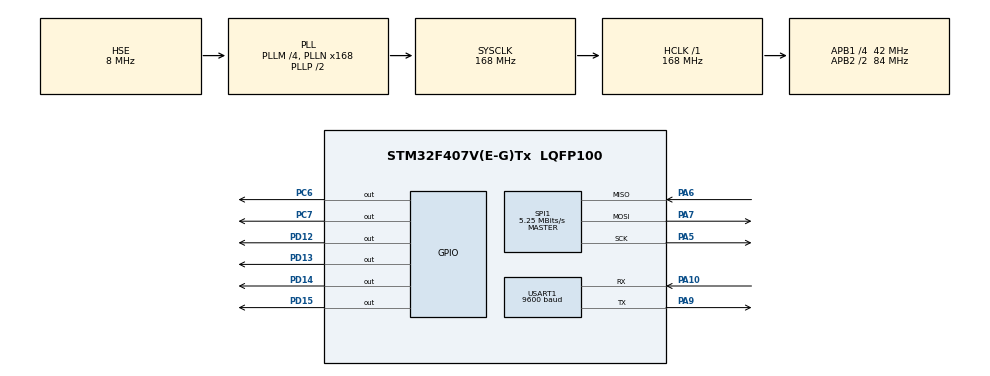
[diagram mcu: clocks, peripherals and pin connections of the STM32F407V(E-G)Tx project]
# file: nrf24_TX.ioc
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Mcu.Family=STM32F4
RCC.PLLSourceVirtual=RCC_PLLSOURCE_HSE
PA6.Mode=Full_Duplex_Master
PH0-OSC_IN.Signal=RCC_OSC_IN
RCC.CortexFreq_Value=168000000
PA7.Mode=Full_Duplex_Master
PA10.Mode=Asynchronous
SPI1.VirtualType=VM_MASTER
USART1.BaudRate=9600
PC6.Signal=GPIO_Output
RCC.APB1CLKDivider=RCC_HCLK_DIV4
RCC.SYSCLKSource=RCC_SYSCLKSOURCE_PLLCLK
ProjectManager.StackSize=0x400
PD13.Signal=GPIO_Output
PA9.Mode=Asynchronous
ProjectManager.TargetToolchain=STM32CubeIDE
SPI1.Direction=SPI_DIRECTION_2LINES
RCC.HCLKFreq_Value=168000000
RCC.APB2TimFreq_Value=168000000
PA9.Signal=USART1_TX
PC7.Signal=GPIO_Output
SPI1.CalculateBaudRate=5.25 MBits/s
RCC.LSE_VALUE=32768
RCC.AHBFreq_Value=168000000
PH0-OSC_IN.Mode=HSE-External-Oscillator
PA5.Signal=SPI1_SCK
RCC.HSE_VALUE=8000000
board=custom
RCC.VCOOutputFreq_Value=336000000
NVIC.SPI1_IRQn=true\:0\:0\:false\:false\:true\:true\:true
RCC.APB2Freq_Value=84000000
SPI1.Mode=SPI_MODE_MASTER
PH1-OSC_OUT.Signal=RCC_OSC_OUT
Mcu.Name=STM32F407V(E-G)Tx
PD14.Signal=GPIO_Output
PH1-OSC_OUT.Mode=HSE-External-Oscillator
RCC.48MHZClocksFreq_Value=84000000
RCC.SYSCLKFreq_VALUE=168000000
Mcu.Package=LQFP100
PA6.Signal=SPI1_MISO
PD12.Signal=GPIO_Output
USART1.VirtualMode=VM_ASYNC
PA10.Signal=USART1_RX
ProjectManager.HeapSize=0x200
RCC.HSI_VALUE=16000000
NVIC.PriorityGroup=NVIC_PRIORITYGROUP_4
RCC.APB2CLKDivider=RCC_HCLK_DIV2
RCC.PLLM=4
RCC.PLLN=168
RCC.APB1TimFreq_Value=84000000
NVIC.USART1_IRQn=true\:0\:0\:false\:false\:true\:true\:true
RCC.APB1Freq_Value=42000000
SPI1.BaudRatePrescaler=SPI_BAUDRATEPRESCALER_16
PD15.Signal=GPIO_Output
PA5.Mode=Full_Duplex_Master
PA7.Signal=SPI1_MOSI

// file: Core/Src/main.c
/* USER CODE BEGIN Header */
/**
  ******************************************************************************
  * @file           : main.c
  * @brief          : Main program body
  ******************************************************************************
  * @attention
  *
  * <h2><center>&copy; Copyright (c) 2021 STMicroelectronics.
  * All rights reserved.</center></h2>
  *
  * This software component is licensed by ST under BSD 3-Clause license,
  * the "License"; You may not use this file except in compliance with the
  * License. You may obtain a copy of the License at:
  *                        opensource.org/licenses/BSD-3-Clause
  *
  ******************************************************************************
  */
/* USER CODE END Header */
#include "main.h"

SPI_HandleTypeDef hspi1;

UART_HandleTypeDef huart1;

void SystemClock_Config(void);
static void MX_GPIO_Init(void);
static void MX_SPI1_Init(void);
static void MX_USART1_UART_Init(void);

/* USER CODE BEGIN 0 */
uint8_t RxData[32];
uint8_t flag=0;
uint8_t data[50];
uint8_t Tx=0,Rx;
uint8_t TxData[] = "Hell";
uint8_t dt_reg,buf1[20];
char str1[]="Hell";
extern uint8_t RX_BUF;
uint8_t fifostatus;
extern rx_flag,tx_flag;
/* USER CODE END 0 */

int main(void)
{

  /* MCU Configuration--------------------------------------------------------*/

  /* Reset of all peripherals, Initializes the Flash interface and the Systick. */
  HAL_Init();

  /* Configure the system clock */
  SystemClock_Config();

  /* Initialize all configured peripherals */
  MX_GPIO_Init();
  MX_SPI1_Init();
  MX_USART1_UART_Init();
  /* USER CODE BEGIN 2 */
  NRF24_ini();
  /* USER CODE END 2 */

  /* Infinite loop */
  while (1)
  {
	flag=NRF24L01_Send(TxData);
	HAL_Delay(1000);
  }
}

void SystemClock_Config(void)
{
  RCC_OscInitTypeDef RCC_OscInitStruct = {0};
  RCC_ClkInitTypeDef RCC_ClkInitStruct = {0};

  /** Configure the main internal regulator output voltage
  */
  __HAL_RCC_PWR_CLK_ENABLE();
  __HAL_PWR_VOLTAGESCALING_CONFIG(PWR_REGULATOR_VOLTAGE_SCALE1);
  /** Initializes the RCC Oscillators according to the specified parameters
  * in the RCC_OscInitTypeDef structure.
  */
  RCC_OscInitStruct.OscillatorType = RCC_OSCILLATORTYPE_HSE;
  RCC_OscInitStruct.HSEState = RCC_HSE_ON;
  RCC_OscInitStruct.PLL.PLLState = RCC_PLL_ON;
  RCC_OscInitStruct.PLL.PLLSource = RCC_PLLSOURCE_HSE;
  RCC_OscInitStruct.PLL.PLLM = 4;
  RCC_OscInitStruct.PLL.PLLN = 168;
  RCC_OscInitStruct.PLL.PLLP = RCC_PLLP_DIV2;
  RCC_OscInitStruct.PLL.PLLQ = 4;
  if (HAL_RCC_OscConfig(&RCC_OscInitStruct) != HAL_OK)
  {
    Error_Handler();
  }
  /** Initializes the CPU, AHB and APB buses clocks
  */
  RCC_ClkInitStruct.ClockType = RCC_CLOCKTYPE_HCLK|RCC_CLOCKTYPE_SYSCLK
                              |RCC_CLOCKTYPE_PCLK1|RCC_CLOCKTYPE_PCLK2;
  RCC_ClkInitStruct.SYSCLKSource = RCC_SYSCLKSOURCE_PLLCLK;
  RCC_ClkInitStruct.AHBCLKDivider = RCC_SYSCLK_DIV1;
  RCC_ClkInitStruct.APB1CLKDivider = RCC_HCLK_DIV4;
  RCC_ClkInitStruct.APB2CLKDivider = RCC_HCLK_DIV2;

  if (HAL_RCC_ClockConfig(&RCC_ClkInitStruct, FLASH_LATENCY_5) != HAL_OK)
  {
    Error_Handler();
  }
}

static void MX_SPI1_Init(void)
{

  /* SPI1 parameter configuration*/
  hspi1.Instance = SPI1;
  hspi1.Init.Mode = SPI_MODE_MASTER;
  hspi1.Init.Direction = SPI_DIRECTION_2LINES;
  hspi1.Init.DataSize = SPI_DATASIZE_8BIT;
  hspi1.Init.CLKPolarity = SPI_POLARITY_LOW;
  hspi1.Init.CLKPhase = SPI_PHASE_1EDGE;
  hspi1.Init.NSS = SPI_NSS_SOFT;
  hspi1.Init.BaudRatePrescaler = SPI_BAUDRATEPRESCALER_16;
  hspi1.Init.FirstBit = SPI_FIRSTBIT_MSB;
  hspi1.Init.TIMode = SPI_TIMODE_DISABLE;
  hspi1.Init.CRCCalculation = SPI_CRCCALCULATION_DISABLE;
  hspi1.Init.CRCPolynomial = 10;
  if (HAL_SPI_Init(&hspi1) != HAL_OK)
  {
    Error_Handler();
  }

}

static void MX_USART1_UART_Init(void)
{

  huart1.Instance = USART1;
  huart1.Init.BaudRate = 9600;
  huart1.Init.WordLength = UART_WORDLENGTH_8B;
  huart1.Init.StopBits = UART_STOPBITS_1;
  huart1.Init.Parity = UART_PARITY_NONE;
  huart1.Init.Mode = UART_MODE_TX_RX;
  huart1.Init.HwFlowCtl = UART_HWCONTROL_NONE;
  huart1.Init.OverSampling = UART_OVERSAMPLING_16;
  if (HAL_UART_Init(&huart1) != HAL_OK)
  {
    Error_Handler();
  }

}

static void MX_GPIO_Init(void)
{
  GPIO_InitTypeDef GPIO_InitStruct = {0};

  /* GPIO Ports Clock Enable */
  __HAL_RCC_GPIOH_CLK_ENABLE();
  __HAL_RCC_GPIOA_CLK_ENABLE();
  __HAL_RCC_GPIOD_CLK_ENABLE();
  __HAL_RCC_GPIOC_CLK_ENABLE();

  /*Configure GPIO pin Output Level */
  HAL_GPIO_WritePin(GPIOD, GPIO_PIN_12|GPIO_PIN_13|GPIO_PIN_14|GPIO_PIN_15, GPIO_PIN_RESET);

  /*Configure GPIO pin Output Level */
  HAL_GPIO_WritePin(GPIOC, GPIO_PIN_6|GPIO_PIN_7, GPIO_PIN_RESET);

  /*Configure GPIO pins : PD12 PD13 PD14 PD15 */
  GPIO_InitStruct.Pin = GPIO_PIN_12|GPIO_PIN_13|GPIO_PIN_14|GPIO_PIN_15;
  GPIO_InitStruct.Mode = GPIO_MODE_OUTPUT_PP;
  GPIO_InitStruct.Pull = GPIO_NOPULL;
  GPIO_InitStruct.Speed = GPIO_SPEED_FREQ_LOW;
  HAL_GPIO_Init(GPIOD, &GPIO_InitStruct);

  /*Configure GPIO pins : PC6 PC7 */
  GPIO_InitStruct.Pin = GPIO_PIN_6|GPIO_PIN_7;
  GPIO_InitStruct.Mode = GPIO_MODE_OUTPUT_PP;
  GPIO_InitStruct.Pull = GPIO_NOPULL;
  GPIO_InitStruct.Speed = GPIO_SPEED_FREQ_LOW;
  HAL_GPIO_Init(GPIOC, &GPIO_InitStruct);

}

void Error_Handler(void)
{
  __disable_irq();
  while (1)
  {
  }
}

/************************ (C) COPYRIGHT STMicroelectronics *****END OF FILE****/
